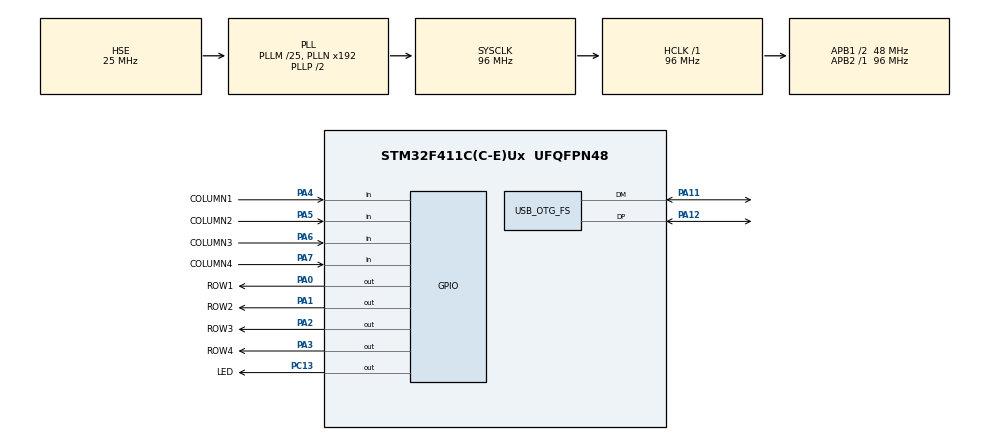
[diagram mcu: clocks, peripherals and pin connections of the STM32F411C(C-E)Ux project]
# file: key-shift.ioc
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Mcu.Family=STM32F4
Mcu.Name=STM32F411C(C-E)Ux
Mcu.Package=UFQFPN48
NVIC.OTG_FS_IRQn=true\:0\:0\:false\:false\:true\:true\:true\:true
NVIC.PriorityGroup=NVIC_PRIORITYGROUP_4
NVIC.TIM1_BRK_TIM9_IRQn=true\:15\:0\:false\:false\:true\:true\:true\:true
NVIC.TimeBase=TIM1_BRK_TIM9_IRQn
NVIC.TimeBaseIP=TIM9
PA0-WKUP.GPIO_Label=ROW1
PA0-WKUP.GPIO_ModeDefaultOutputPP=GPIO_MODE_OUTPUT_OD
PA0-WKUP.GPIO_PuPd=GPIO_NOPULL
PA0-WKUP.PinState=GPIO_PIN_SET
PA0-WKUP.Signal=GPIO_Output
PA1.GPIO_Label=ROW2
PA1.GPIO_ModeDefaultOutputPP=GPIO_MODE_OUTPUT_OD
PA1.GPIO_PuPd=GPIO_NOPULL
PA1.PinState=GPIO_PIN_SET
PA1.Signal=GPIO_Output
PA11.Mode=Device_Only
PA11.Signal=USB_OTG_FS_DM
PA12.Mode=Device_Only
PA12.Signal=USB_OTG_FS_DP
PA2.GPIO_Label=ROW3
PA2.GPIO_ModeDefaultOutputPP=GPIO_MODE_OUTPUT_OD
PA2.GPIO_PuPd=GPIO_NOPULL
PA2.PinState=GPIO_PIN_SET
PA2.Signal=GPIO_Output
PA3.GPIO_Label=ROW4
PA3.GPIO_ModeDefaultOutputPP=GPIO_MODE_OUTPUT_OD
PA3.GPIO_PuPd=GPIO_NOPULL
PA3.PinState=GPIO_PIN_SET
PA3.Signal=GPIO_Output
PA4.GPIO_Label=COLUMN1
PA4.GPIO_PuPd=GPIO_PULLUP
PA4.Signal=GPIO_Input
PA5.GPIO_Label=COLUMN2
PA5.GPIO_PuPd=GPIO_PULLUP
PA5.Signal=GPIO_Input
PA6.GPIO_Label=COLUMN3
PA6.GPIO_PuPd=GPIO_PULLUP
PA6.Signal=GPIO_Input
PA7.GPIO_Label=COLUMN4
PA7.GPIO_PuPd=GPIO_PULLUP
PA7.Signal=GPIO_Input
PC13-ANTI_TAMP.GPIO_Label=LED
PC13-ANTI_TAMP.PinState=GPIO_PIN_SET
PC13-ANTI_TAMP.Signal=GPIO_Output
PC14-OSC32_IN.Mode=LSE-External-Oscillator
PC14-OSC32_IN.Signal=RCC_OSC32_IN
PC15-OSC32_OUT.Mode=LSE-External-Oscillator
PC15-OSC32_OUT.Signal=RCC_OSC32_OUT
PH0\ -\ OSC_IN.Mode=HSE-External-Oscillator
PH0\ -\ OSC_IN.Signal=RCC_OSC_IN
PH1\ -\ OSC_OUT.Mode=HSE-External-Oscillator
PH1\ -\ OSC_OUT.Signal=RCC_OSC_OUT
ProjectManager.HeapSize=0x200
ProjectManager.StackSize=0x400
ProjectManager.TargetToolchain=CMake
RCC.48MHZClocksFreq_Value=48000000
RCC.AHBFreq_Value=96000000
RCC.APB1CLKDivider=RCC_HCLK_DIV2
RCC.APB1Freq_Value=48000000
RCC.APB1TimFreq_Value=96000000
RCC.APB2Freq_Value=96000000
RCC.APB2TimFreq_Value=96000000
RCC.CortexFreq_Value=96000000
RCC.HCLKFreq_Value=96000000
RCC.HSE_VALUE=25000000
RCC.HSI_VALUE=16000000
RCC.PLLM=25
RCC.SYSCLKFreq_VALUE=96000000
RCC.SYSCLKSource=RCC_SYSCLKSOURCE_PLLCLK
RCC.VCOOutputFreq_Value=192000000
STMicroelectronics.X-CUBE-AZRTOS-F4.1.1.0.AZRTOS_APP_MEM_ALLOCATION_METHOD=1
STMicroelectronics.X-CUBE-AZRTOS-F4.1.1.0.USBD_CDCACM_EPINCMD_ADDR=2
STMicroelectronics.X-CUBE-AZRTOS-F4.1.1.0.USBD_CDCACM_EPIN_ADDR=3
STMicroelectronics.X-CUBE-AZRTOS-F4.1.1.0.USBD_CDCACM_EPOUT_ADDR=4
STMicroelectronics.X-CUBE-AZRTOS-F4.1.1.0.UX_DEVICE_APP_MEM_POOL_SIZE=16*1024
STMicroelectronics.X-CUBE-AZRTOS-F4.1.1.0.UX_MAX_SLAVE_CLASS_DRIVER=2
STMicroelectronics.X-CUBE-AZRTOS-F4.1.1.0.UX_SLAVE_REQUEST_DATA_MAX_LENGTH=512
STMicroelectronics.X-CUBE-AZRTOS-F4.1.1.0_IsAnAzureRtosMw=true
USB_OTG_FS.VirtualMode=Device_Only
VP_SYS_VS_tim9.Mode=TIM9
board=custom

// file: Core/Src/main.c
/* USER CODE BEGIN Header */
/**
  ******************************************************************************
  * @file           : main.c
  * @brief          : Main program body
  ******************************************************************************
  * @attention
  *
  * Copyright (c) 2025 STMicroelectronics.
  * All rights reserved.
  *
  * This software is licensed under terms that can be found in the LICENSE file
  * in the root directory of this software component.
  * If no LICENSE file comes with this software, it is provided AS-IS.
  *
  ******************************************************************************
  */
/* USER CODE END Header */
#include "main.h"
#include "gpio.h"

/* USER CODE BEGIN Includes */
#include "app_threadx.h"

/* USER CODE END Includes */

void SystemClock_Config(void);

int main(void)
{

  /* MCU Configuration--------------------------------------------------------*/

  /* Reset of all peripherals, Initializes the Flash interface and the Systick. */
  HAL_Init();

  /* Configure the system clock */
  SystemClock_Config();

  /* Initialize all configured peripherals */
  MX_GPIO_Init();
  /* USER CODE BEGIN 2 */
  MX_ThreadX_Init();
  /* We should never get here as control is now taken by the scheduler */
  /* USER CODE END 2 */

  /* Infinite loop */
  while (1)
  {

  }
}

void SystemClock_Config(void)
{
  RCC_OscInitTypeDef RCC_OscInitStruct = {0};
  RCC_ClkInitTypeDef RCC_ClkInitStruct = {0};

  /** Configure the main internal regulator output voltage
  */
  __HAL_RCC_PWR_CLK_ENABLE();
  __HAL_PWR_VOLTAGESCALING_CONFIG(PWR_REGULATOR_VOLTAGE_SCALE1);

  /** Initializes the RCC Oscillators according to the specified parameters
  * in the RCC_OscInitTypeDef structure.
  */
  RCC_OscInitStruct.OscillatorType = RCC_OSCILLATORTYPE_HSE;
  RCC_OscInitStruct.HSEState = RCC_HSE_ON;
  RCC_OscInitStruct.PLL.PLLState = RCC_PLL_ON;
  RCC_OscInitStruct.PLL.PLLSource = RCC_PLLSOURCE_HSE;
  RCC_OscInitStruct.PLL.PLLM = 25;
  RCC_OscInitStruct.PLL.PLLN = 192;
  RCC_OscInitStruct.PLL.PLLP = RCC_PLLP_DIV2;
  RCC_OscInitStruct.PLL.PLLQ = 4;
  if (HAL_RCC_OscConfig(&RCC_OscInitStruct) != HAL_OK)
  {
    Error_Handler();
  }

  /** Initializes the CPU, AHB and APB buses clocks
  */
  RCC_ClkInitStruct.ClockType = RCC_CLOCKTYPE_HCLK|RCC_CLOCKTYPE_SYSCLK
                              |RCC_CLOCKTYPE_PCLK1|RCC_CLOCKTYPE_PCLK2;
  RCC_ClkInitStruct.SYSCLKSource = RCC_SYSCLKSOURCE_PLLCLK;
  RCC_ClkInitStruct.AHBCLKDivider = RCC_SYSCLK_DIV1;
  RCC_ClkInitStruct.APB1CLKDivider = RCC_HCLK_DIV2;
  RCC_ClkInitStruct.APB2CLKDivider = RCC_HCLK_DIV1;

  if (HAL_RCC_ClockConfig(&RCC_ClkInitStruct, FLASH_LATENCY_3) != HAL_OK)
  {
    Error_Handler();
  }
}

/* USER CODE BEGIN 4 */
void process_key(int row, int column) {
  HAL_GPIO_WritePin(LED_GPIO_Port, LED_Pin, GPIO_PIN_RESET);
}
/* USER CODE END 4 */

void HAL_TIM_PeriodElapsedCallback(TIM_HandleTypeDef *htim)
{
  if (htim->Instance == TIM9)
  {
    HAL_IncTick();
  }
}

void Error_Handler(void)
{
  __disable_irq();
  while (1)
  {
  }
}
